VERSION ""

NS_ :

BS_:

BU_: BMS Third_Party_Device

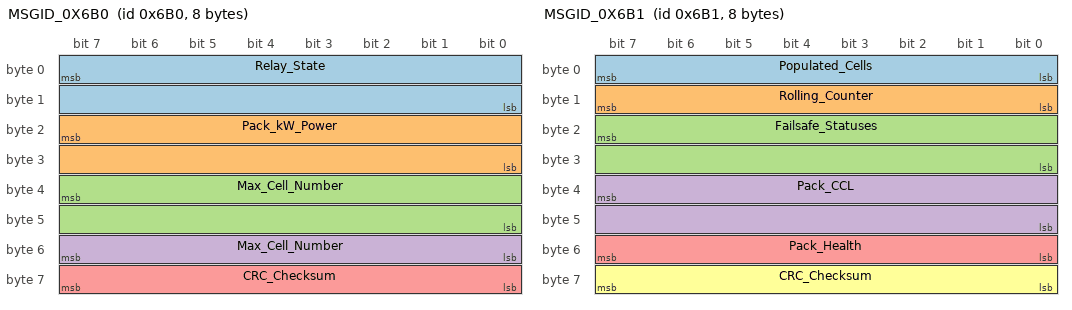
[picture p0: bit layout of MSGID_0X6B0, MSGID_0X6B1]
BO_ 1712 MSGID_0X6B0: 8 BMS
 SG_ Relay_State : 7|16@0+ (1.0,0) [0|0] ""  Third_Party_Device
 SG_ Pack_kW_Power : 23|16@0+ (0.1,0) [0|0] "kW"  Third_Party_Device
 SG_ Max_Cell_Number : 39|16@0+ (1.0,0) [0|0] "Num"  Third_Party_Device
 SG_ Max_Cell_Number : 55|8@0+ (1.0,0) [0|0] "Num"  Third_Party_Device
 SG_ CRC_Checksum : 63|8@0+ (1.0,1720) [0|0] ""  Third_Party_Device

BO_ 1713 MSGID_0X6B1: 8 BMS
 SG_ Populated_Cells : 7|8@0+ (1.0,0) [0|0] "Num"  Third_Party_Device
 SG_ Rolling_Counter : 15|8@0+ (1.0,0) [0|0] "Num"  Third_Party_Device
 SG_ Failsafe_Statuses : 23|16@0+ (1.0,0) [0|0] ""  Third_Party_Device
 SG_ Pack_CCL : 39|16@0+ (1.0,0) [0|0] "Amps"  Third_Party_Device
 SG_ Pack_Health : 55|8@0+ (1.0,0) [0|0] "Percent"  Third_Party_Device
 SG_ CRC_Checksum : 63|8@0+ (1.0,1721) [0|0] ""  Third_Party_Device

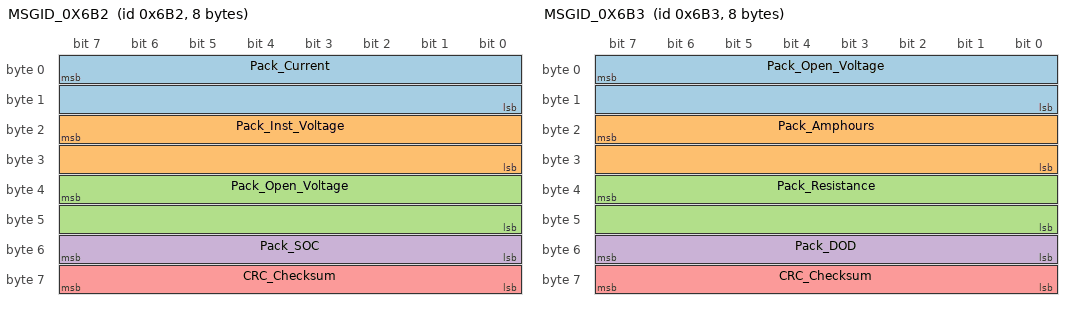
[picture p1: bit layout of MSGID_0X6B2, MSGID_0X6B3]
BO_ 1714 MSGID_0X6B2: 8 BMS
 SG_ Pack_Current : 7|16@0+ (0.1,0) [0|0] "Amps"  Third_Party_Device
 SG_ Pack_Inst_Voltage : 23|16@0+ (0.1,0) [0|0] "Volts"  Third_Party_Device
 SG_ Pack_Open_Voltage : 39|16@0+ (0.1,0) [0|0] "Volts"  Third_Party_Device
 SG_ Pack_SOC : 55|8@0+ (0.5,0) [0|0] "Percent"  Third_Party_Device
 SG_ CRC_Checksum : 63|8@0+ (1.0,0) [0|0] ""  Third_Party_Device

BO_ 1715 MSGID_0X6B3: 8 BMS
 SG_ Pack_Open_Voltage : 7|16@0+ (0.1,0) [0|0] "Volts"  Third_Party_Device
 SG_ Pack_Amphours : 23|16@0+ (0.1,0) [0|0] "Amphours"  Third_Party_Device
 SG_ Pack_Resistance : 39|16@0+ (0.001,0) [0|0] "Ohms"  Third_Party_Device
 SG_ Pack_DOD : 55|8@0+ (0.5,0) [0|0] "Percent"  Third_Party_Device
 SG_ CRC_Checksum : 63|8@0+ (1.0,0) [0|0] ""  Third_Party_Device

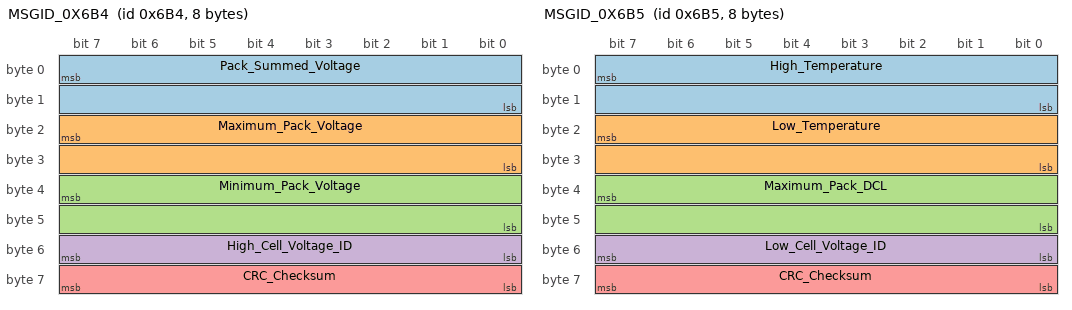
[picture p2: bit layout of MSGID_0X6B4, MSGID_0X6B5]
BO_ 1716 MSGID_0X6B4: 8 BMS
 SG_ Pack_Summed_Voltage : 7|16@0+ (0.01,0) [0|0] "Volts"  Third_Party_Device
 SG_ Maximum_Pack_Voltage : 23|16@0+ (0.1,0) [0|0] "Volts"  Third_Party_Device
 SG_ Minimum_Pack_Voltage : 39|16@0+ (0.1,0) [0|0] "Volts"  Third_Party_Device
 SG_ High_Cell_Voltage_ID : 55|8@0+ (1.0,0) [0|0] "ID"  Third_Party_Device
 SG_ CRC_Checksum : 63|8@0+ (1.0,0) [0|0] ""  Third_Party_Device

BO_ 1717 MSGID_0X6B5: 8 BMS
 SG_ High_Temperature : 7|16@0+ (1.0,0) [0|0] "Celsius"  Third_Party_Device
 SG_ Low_Temperature : 23|16@0+ (1.0,0) [0|0] "Celsius"  Third_Party_Device
 SG_ Maximum_Pack_DCL : 39|16@0+ (1.0,0) [0|0] "Amps"  Third_Party_Device
 SG_ Low_Cell_Voltage_ID : 55|8@0+ (1.0,0) [0|0] "ID"  Third_Party_Device
 SG_ CRC_Checksum : 63|8@0+ (1.0,0) [0|0] ""  Third_Party_Device

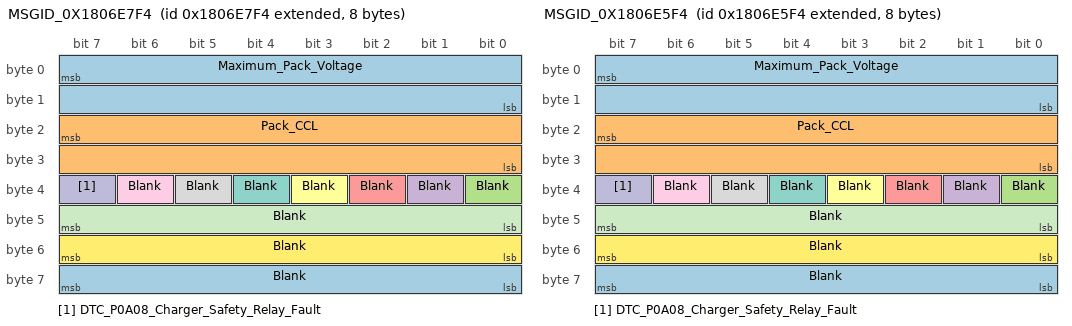
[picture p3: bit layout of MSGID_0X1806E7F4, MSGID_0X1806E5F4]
BO_ 2550589428 MSGID_0X1806E7F4: 8 BMS
 SG_ Maximum_Pack_Voltage : 7|16@0+ (0.1,0) [0|0] "Volts"  Third_Party_Device
 SG_ Pack_CCL : 23|16@0+ (0.1,0) [0|0] "Amps"  Third_Party_Device
 SG_ Blank : 32|1@1+ (1.0,0) [0|1] ""  Third_Party_Device
 SG_ Blank : 33|1@1+ (1.0,0) [0|1] ""  Third_Party_Device
 SG_ Blank : 34|1@1+ (1.0,0) [0|1] ""  Third_Party_Device
 SG_ Blank : 35|1@1+ (1.0,0) [0|1] ""  Third_Party_Device
 SG_ Blank : 36|1@1+ (1.0,0) [0|1] ""  Third_Party_Device
 SG_ Blank : 37|1@1+ (1.0,0) [0|1] ""  Third_Party_Device
 SG_ Blank : 38|1@1+ (1.0,0) [0|1] ""  Third_Party_Device
 SG_ DTC_P0A08_Charger_Safety_Relay_Fault : 39|1@1+ (1.0,0) [0|1] ""  Third_Party_Device
 SG_ Blank : 47|8@0+ (0.1,0) [0|0] ""  Third_Party_Device
 SG_ Blank : 55|8@0+ (1.0,0) [0|0] ""  Third_Party_Device
 SG_ Blank : 63|8@0+ (1.0,0) [0|0] ""  Third_Party_Device

BO_ 2550588916 MSGID_0X1806E5F4: 8 BMS
 SG_ Maximum_Pack_Voltage : 7|16@0+ (0.1,0) [0|0] "Volts"  Third_Party_Device
 SG_ Pack_CCL : 23|16@0+ (0.1,0) [0|0] "Amps"  Third_Party_Device
 SG_ Blank : 32|1@1+ (1.0,0) [0|1] ""  Third_Party_Device
 SG_ Blank : 33|1@1+ (1.0,0) [0|1] ""  Third_Party_Device
 SG_ Blank : 34|1@1+ (1.0,0) [0|1] ""  Third_Party_Device
 SG_ Blank : 35|1@1+ (1.0,0) [0|1] ""  Third_Party_Device
 SG_ Blank : 36|1@1+ (1.0,0) [0|1] ""  Third_Party_Device
 SG_ Blank : 37|1@1+ (1.0,0) [0|1] ""  Third_Party_Device
 SG_ Blank : 38|1@1+ (1.0,0) [0|1] ""  Third_Party_Device
 SG_ DTC_P0A08_Charger_Safety_Relay_Fault : 39|1@1+ (1.0,0) [0|1] ""  Third_Party_Device
 SG_ Blank : 47|8@0+ (0.1,0) [0|0] ""  Third_Party_Device
 SG_ Blank : 55|8@0+ (1.0,0) [0|0] ""  Third_Party_Device
 SG_ Blank : 63|8@0+ (1.0,0) [0|0] ""  Third_Party_Device

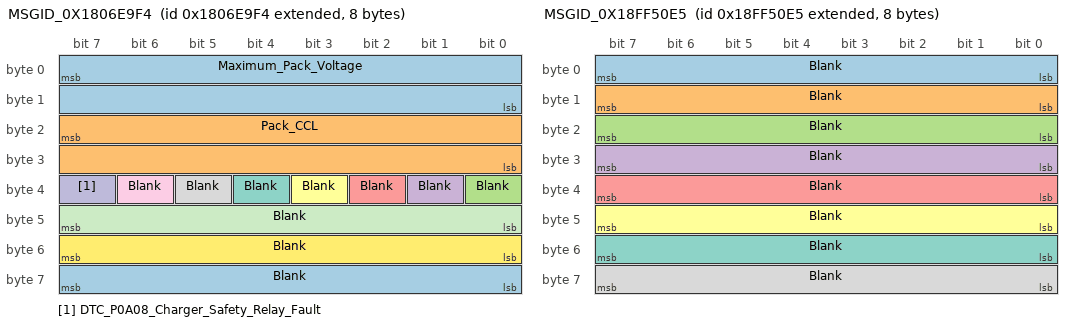
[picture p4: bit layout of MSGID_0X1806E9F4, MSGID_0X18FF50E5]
BO_ 2550589940 MSGID_0X1806E9F4: 8 BMS
 SG_ Maximum_Pack_Voltage : 7|16@0+ (0.1,0) [0|0] "Volts"  Third_Party_Device
 SG_ Pack_CCL : 23|16@0+ (0.1,0) [0|0] "Amps"  Third_Party_Device
 SG_ Blank : 32|1@1+ (1.0,0) [0|1] ""  Third_Party_Device
 SG_ Blank : 33|1@1+ (1.0,0) [0|1] ""  Third_Party_Device
 SG_ Blank : 34|1@1+ (1.0,0) [0|1] ""  Third_Party_Device
 SG_ Blank : 35|1@1+ (1.0,0) [0|1] ""  Third_Party_Device
 SG_ Blank : 36|1@1+ (1.0,0) [0|1] ""  Third_Party_Device
 SG_ Blank : 37|1@1+ (1.0,0) [0|1] ""  Third_Party_Device
 SG_ Blank : 38|1@1+ (1.0,0) [0|1] ""  Third_Party_Device
 SG_ DTC_P0A08_Charger_Safety_Relay_Fault : 39|1@1+ (1.0,0) [0|1] ""  Third_Party_Device
 SG_ Blank : 47|8@0+ (1.0,0) [0|0] ""  Third_Party_Device
 SG_ Blank : 55|8@0+ (1.0,0) [0|0] ""  Third_Party_Device
 SG_ Blank : 63|8@0+ (1.0,0) [0|0] ""  Third_Party_Device

BO_ 2566869221 MSGID_0X18FF50E5: 8 Third_Party_Device
 SG_ Blank : 7|8@0+ (1.0,0) [0|0] ""  BMS
 SG_ Blank : 15|8@0+ (1.0,0) [0|0] ""  BMS
 SG_ Blank : 23|8@0+ (1.0,0) [0|0] ""  BMS
 SG_ Blank : 31|8@0+ (1.0,0) [0|0] ""  BMS
 SG_ Blank : 39|8@0+ (1.0,0) [0|0] ""  BMS
 SG_ Blank : 47|8@0+ (1.0,0) [0|0] ""  BMS
 SG_ Blank : 55|8@0+ (1.0,0) [0|0] ""  BMS
 SG_ Blank : 63|8@0+ (1.0,0) [0|0] ""  BMS

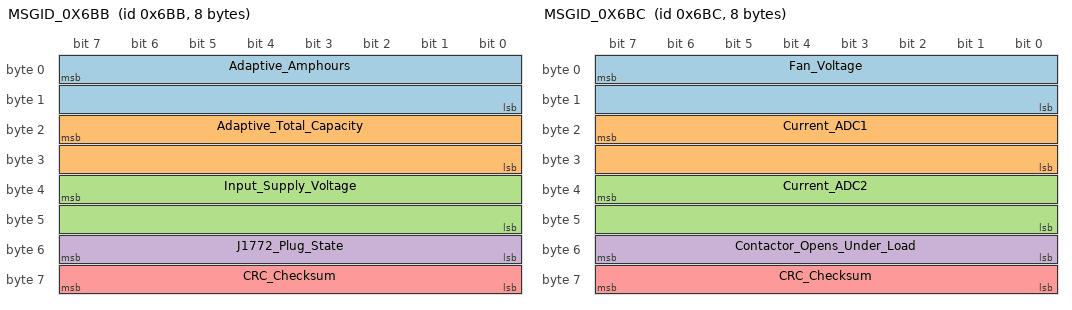
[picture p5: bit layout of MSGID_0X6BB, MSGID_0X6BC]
BO_ 1723 MSGID_0X6BB: 8 BMS
 SG_ Adaptive_Amphours : 7|16@0+ (0.1,0) [0|0] "Amphours"  Third_Party_Device
 SG_ Adaptive_Total_Capacity : 23|16@0+ (0.010000000000000002,0) [0|0] "Amphours"  Third_Party_Device
 SG_ Input_Supply_Voltage : 39|16@0+ (0.1,7) [0|0] "Volts"  Third_Party_Device
 SG_ J1772_Plug_State : 55|8@0+ (1.0,0) [0|0] ""  Third_Party_Device
 SG_ CRC_Checksum : 63|8@0+ (1.0,0) [0|0] ""  Third_Party_Device

BO_ 1724 MSGID_0X6BC: 8 BMS
 SG_ Fan_Voltage : 7|16@0+ (0.01,0) [0|0] "Volts"  Third_Party_Device
 SG_ Current_ADC1 : 23|16@0+ (0.1,0) [0|0] ""  Third_Party_Device
 SG_ Current_ADC2 : 39|16@0+ (1.0,7) [0|0] ""  Third_Party_Device
 SG_ Contactor_Opens_Under_Load : 55|8@0+ (1.0,0) [0|0] "#"  Third_Party_Device
 SG_ CRC_Checksum : 63|8@0+ (1.0,0) [0|0] ""  Third_Party_Device

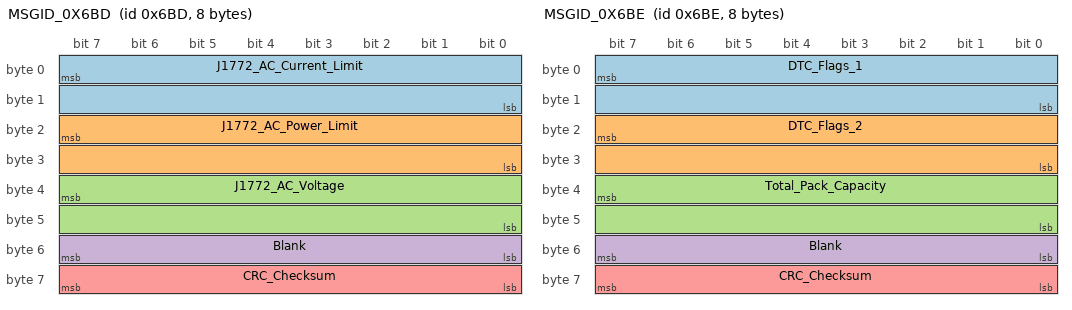
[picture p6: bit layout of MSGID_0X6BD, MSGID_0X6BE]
BO_ 1725 MSGID_0X6BD: 8 BMS
 SG_ J1772_AC_Current_Limit : 7|16@0+ (1.0,0) [0|0] "Amps"  Third_Party_Device
 SG_ J1772_AC_Power_Limit : 23|16@0+ (0.1,0) [0|0] "Watts"  Third_Party_Device
 SG_ J1772_AC_Voltage : 39|16@0+ (0.1,7) [0|0] "Volts"  Third_Party_Device
 SG_ Blank : 55|8@0+ (1.0,0) [0|0] ""  Third_Party_Device
 SG_ CRC_Checksum : 63|8@0+ (1.0,0) [0|0] ""  Third_Party_Device

BO_ 1726 MSGID_0X6BE: 8 BMS
 SG_ DTC_Flags_1 : 7|16@0+ (1.0,0) [0|0] ""  Third_Party_Device
 SG_ DTC_Flags_2 : 23|16@0+ (1.0,0) [0|0] ""  Third_Party_Device
 SG_ Total_Pack_Capacity : 39|16@0+ (0.1,0) [0|0] "Ahr"  Third_Party_Device
 SG_ Blank : 55|8@0+ (1.0,0) [0|0] ""  Third_Party_Device
 SG_ CRC_Checksum : 63|8@0+ (1.0,0) [0|0] ""  Third_Party_Device

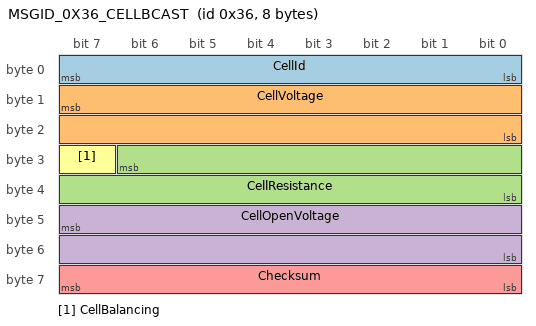
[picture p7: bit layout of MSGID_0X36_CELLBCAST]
BO_ 54 MSGID_0X36_CELLBCAST: 8 BMS
 SG_ CellId : 7|8@0+ (1,0) [0|0] "#" Third_Party_Device
 SG_ CellVoltage : 15|16@0+ (0.0001,0) [0|0] "Volts" Third_Party_Device
 SG_ CellResistance : 30|15@0+ (0.01,0) [0|0] "mOhms" Third_Party_Device
 SG_ CellOpenVoltage : 47|16@0+ (0.0001,0) [0|0] "Volts" Third_Party_Device
 SG_ Checksum : 63|8@0+ (1,0) [0|0] "" Third_Party_Device
 SG_ CellBalancing : 31|1@1+ (1,0) [0|0] "" Third_Party_Device
CM_ BO_ 1712 "This ID Transmits at 256 ms.";
CM_ BO_ 1713 "This ID Transmits at 256 ms.";
CM_ BO_ 1714 "This ID Transmits at 256 ms.";
CM_ BO_ 1715 "This ID Transmits at 256 ms.";
CM_ BO_ 1716 "This ID Transmits at 256 ms.";
CM_ BO_ 1717 "This ID Transmits at 1000 ms.";
CM_ BO_ 2550589428 "This ID Transmits at 808 ms.";
CM_ BO_ 2550588916 "This ID Transmits at 808 ms.";
CM_ BO_ 2550589940 "This ID Transmits at 808 ms.";
CM_ BO_ 1723 "This ID Transmits at 256 ms.";
CM_ BO_ 1724 "This ID Transmits at 256 ms.";
CM_ BO_ 1725 "This ID Transmits at 256 ms.";
CM_ BO_ 1726 "This ID Transmits at 256 ms.";
CM_ BO_ 54 "This ID Transmits at 4 ms.";
CM_ SG_ 54 Checksum "Value = (0x36 + 8 + byte0 + byte1 + ... + byte6) & 0xFF";
